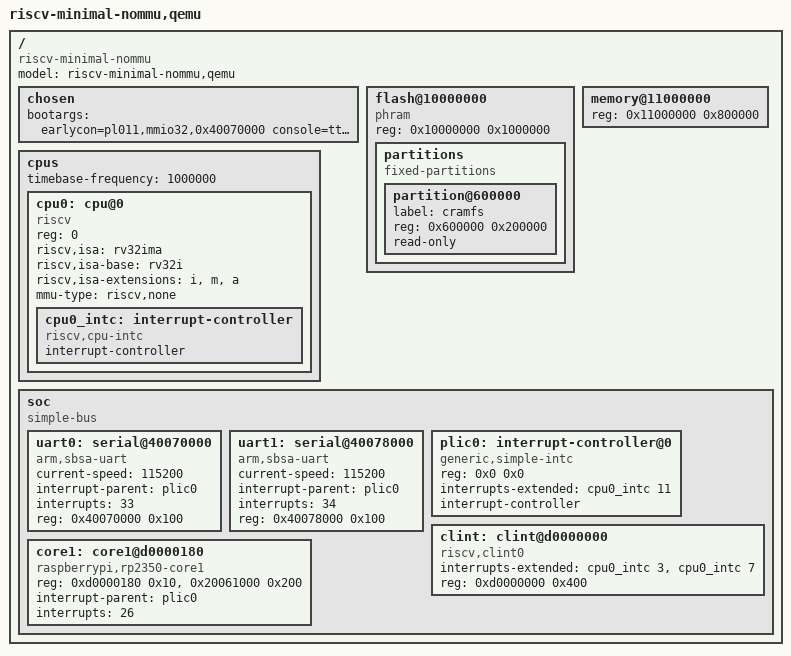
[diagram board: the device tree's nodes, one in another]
/dts-v1/;

/ {
	#address-cells = <1>;
	#size-cells = <1>;
	compatible = "riscv-minimal-nommu";
	model = "riscv-minimal-nommu,qemu";

	chosen {
		bootargs = "earlycon=pl011,mmio32,0x40070000 console=ttyAMA0 root=mtd:cramfs rootfstype=cramfs ro";
	};

	flash@10000000 {
		compatible = "phram"; /* ROM mapped into physical address space */
		/* reg = <0x10000000  0x800000>; */  /* 8MB Flash Base & Size */
		reg = <0x10000000 0x1000000>;        /* 16MB Flash Base & Size */

		partitions {
			#address-cells = <1>;
			#size-cells = <1>;
			compatible = "fixed-partitions";

			/* partition@0 {
				label = "kernel";
				reg = <0x0 0x200000>;
				read-only;
			}; */

			partition@600000 {
				label = "cramfs";
				reg = <0x600000 0x200000>; /* ~2MB for cramfs at 6MB offset*/
				read-only;
			};
		};
	};

	memory@11000000 {
		device_type = "memory";
		reg = <0x11000000 0x800000>;	/* 8MB */
	};

	cpus {
		#address-cells = <1>;
		#size-cells = <0>;
		/* sys timer is in Hz */
		timebase-frequency = <1000000>;

		cpu0: cpu@0 {
			reg = <0>;
			device_type = "cpu";
			compatible = "riscv";
			riscv,isa = "rv32ima";
			riscv,isa-base = "rv32i";
			riscv,isa-extensions = "i", "m", "a";
			mmu-type = "riscv,none";
			status = "okay";

			cpu0_intc: interrupt-controller {
				#interrupt-cells = <1>;
				#address-cells = <1>;
				interrupt-controller;
				compatible = "riscv,cpu-intc";
			};
		};
	};

	soc {
		#address-cells = <1>;
		#size-cells = <1>;
		compatible = "simple-bus";
		ranges;

		uart0: serial@40070000 {
			compatible = "arm,sbsa-uart";
			current-speed = <115200>;
			interrupt-parent = <&plic0>;
			interrupts = <33>;
			reg = <0x40070000 0x100>;
			status = "okay";
		};

		uart1: serial@40078000 {
			compatible = "arm,sbsa-uart";
			current-speed = <115200>;
			interrupt-parent = <&plic0>;
			interrupts = <34>;
			reg = <0x40078000 0x100>;
			status = "okay";
		};

		plic0: interrupt-controller@0 {
			reg = <0x0 0x0>;
			interrupts-extended = <&cpu0_intc 11>;
			interrupt-controller;
			compatible = "generic,simple-intc";
			#address-cells = <0x00>;
			#interrupt-cells = <0x01>;
		};

		clint: clint@d0000000 {
			interrupts-extended = <&cpu0_intc 3>,
					      <&cpu0_intc 7>;
			reg = <0xd0000000 0x400>;
			compatible = "riscv,clint0";
		};
	};
};

/* core1 coprocessor control (cdev + /sys/class) */
&{/soc} {
	core1: core1@d0000180 {
		compatible = "raspberrypi,rp2350-core1";
		reg = <0xd0000180 0x10>,   /* SIO doorbell OUT_SET..IN_CLR */
		      <0x20061000 0x200>;  /* SRAM: heartbeat/mailbox/pio_job */
		interrupt-parent = <&plic0>;
		interrupts = <26>;         /* SIO_IRQ_BELL */
	};
};
